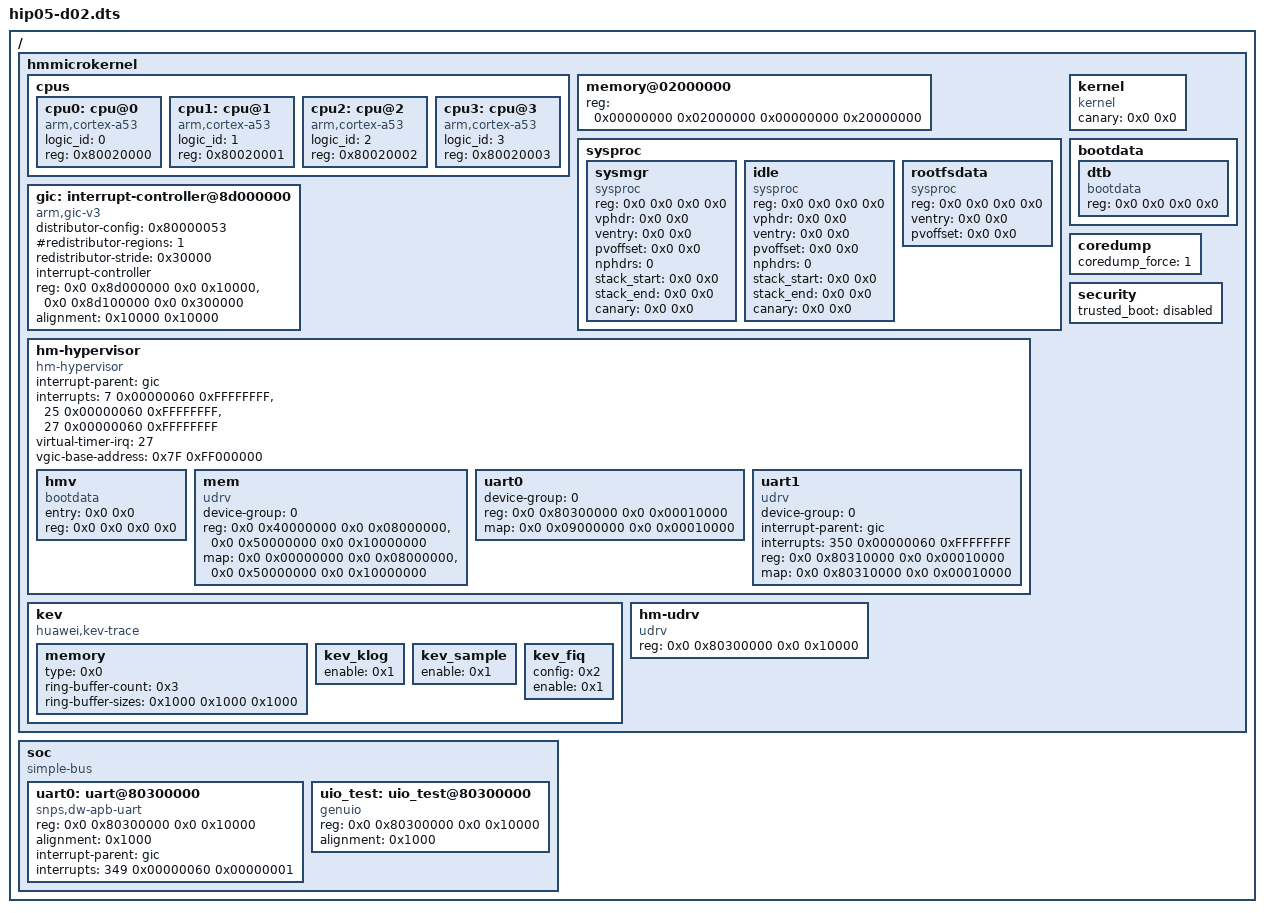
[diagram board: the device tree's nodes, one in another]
/dts-v1/;
/ { #address-cells = <2>; #size-cells = <2>; hmmicrokernel {
	#address-cells = <2>;
	#size-cells = <2>;
	cpus {
		#address-cells = <1>;
		#size-cells = <0>;
		cpu0: cpu@0 {
			compatible = "arm,cortex-a53", "arm,armv8";
			device_type = "cpu";
			logic_id = <0>;
			reg = <0x80020000>;
		};
		cpu1: cpu@1 {
			compatible = "arm,cortex-a53", "arm,armv8";
			device_type = "cpu";
			logic_id = <1>;
			reg = <0x80020001>;
		};
		cpu2: cpu@2 {
			compatible = "arm,cortex-a53", "arm,armv8";
			device_type = "cpu";
			logic_id = <2>;
			reg = <0x80020002>;
		};
		cpu3: cpu@3 {
			compatible = "arm,cortex-a53", "arm,armv8";
			device_type = "cpu";
			logic_id = <3>;
			reg = <0x80020003>;
		};
	};

	memory@02000000 {
		device_type = "memory";
		reg = <0x00000000 0x02000000 0x00000000 0x20000000>;
	};

	sysproc {
		#address-cells = <2>;
		#size-cells = <2>;
		sysmgr {
			compatible = "sysproc", "sysmgr";
			/* filled by bootloader */
			reg      = <0x0 0x0 0x0 0x0>;
			vphdr    = <0x0 0x0>;
			ventry   = <0x0 0x0>;
			pvoffset = <0x0 0x0>;
			nphdrs   = <0>;
			stack_start = <0x0 0x0>;
			stack_end = <0x0 0x0>;
			canary = <0x0 0x0>;
		};
		idle {
			compatible = "sysproc", "idle";
			/* filled by bootloader */
			reg      = <0x0 0x0 0x0 0x0>;
			vphdr    = <0x0 0x0>;
			ventry   = <0x0 0x0>;
			pvoffset = <0x0 0x0>;
			nphdrs   = <0>;
			stack_start = <0x0 0x0>;
			stack_end = <0x0 0x0>;
			canary = <0x0 0x0>;
		};
		rootfsdata {
			compatible = "sysproc", "rootfs";
			/* filled by bootloader */
			reg      = <0x0 0x0 0x0 0x0>;
			ventry   = <0x0 0x0>;
			pvoffset = <0x0 0x0>;
		};
	};

	kernel {
		compatible = "kernel";
		/* filled by bootloader */
		canary = <0x0 0x0>;
	};

	bootdata {
		#address-cells = <2>;
		#size-cells = <2>;
		dtb {
			compatible = "bootdata", "dtb";
			/* filled by bootloader */
			reg = <0x0 0x0 0x0 0x0>;
		};
	};

	gic: interrupt-controller@8d000000 {
		compatible = "arm,gic-v3";

		#address-cells = <2>;
		#size-cells = <2>;

		/* Enable group 0, Group1NS, ARE_NS, Disable Security */
		distributor-config = <0x80000053>;

		#interrupt-cells = <3>;
		#redistributor-regions = <1>;
		redistributor-stride = <0x30000>;
		interrupt-controller;
		reg =   <0x0 0x8d000000 0x0 0x10000>,	/* GICD */
			<0x0 0x8d100000 0x0 0x300000>;	/* GICR */
		alignment = <0x10000 0x10000>;
	};

	hm-hypervisor {
		compatible = "hm-hypervisor";
		#address-cells = <2>;
		#size-cells = <2>;

		interrupt-parent = <&gic>;
		interrupts = < 7 0x00000060 0xFFFFFFFF>,
			     <25 0x00000060 0xFFFFFFFF>,
			     <27 0x00000060 0xFFFFFFFF>;

		virtual-timer-irq = <27>;
		vgic-base-address = <0x7F 0xFF000000>;

		hmv {
			compatible = "bootdata";
			/* filled by bootloader */
			entry = <0x0 0x0>;
			reg = <0x0 0x0 0x0 0x0>;
		};

		mem {
			device-group = <0>;
			compatible = "udrv";
			reg = <0x0 0x40000000 0x0 0x08000000>,
			      <0x0 0x50000000 0x0 0x10000000>;
			map = <0x0 0x00000000 0x0 0x08000000>,
			      <0x0 0x50000000 0x0 0x10000000>;
		};

		uart0 {
			device-group = <0>;
			reg = <0x0 0x80300000 0x0 0x00010000>;
			map = <0x0 0x09000000 0x0 0x00010000>;
		};

		uart1 {
			device-group = <0>;
			compatible = "udrv";
			interrupt-parent = <&gic>;
			interrupts = <350 0x00000060 0xFFFFFFFF>;
			reg = <0x0 0x80310000 0x0 0x00010000>;
			map = <0x0 0x80310000 0x0 0x00010000>;
		};
	};

	kev {
		compatible = "huawei,kev-trace";

		memory {
			type = <0x0>;
			ring-buffer-count = <0x3>;
			ring-buffer-sizes = <0x1000 0x1000 0x1000>;
		};
		kev_klog {
			enable = <0x1>;
		};
		kev_sample {
			enable = <0x1>;
		};
		kev_fiq {
			config = <0x2>;
			enable = <0x1>;
		};
	};

	hm-udrv {
		compatible = "udrv";
		reg = <0x0 0x80300000 0x0 0x10000>;
	};

	coredump {
		coredump_force = <1>;
	};
	security {
		trusted_boot = "disabled";
	};
	};

	soc {
		compatible = "simple-bus";
		#address-cells = <2>;
		#size-cells = <2>;
		ranges;

		uart0: uart@80300000 {
			compatible = "snps,dw-apb-uart", "arm,pl011,uart";
			reg = <0x0 0x80300000 0x0 0x10000>;
			alignment = <0x1000>;

			interrupt-parent = <&gic>;
			interrupts = <349 0x00000060 0x00000001>;
		};

		uio_test: uio_test@80300000 {
			compatible = "genuio";
			reg = <0x0 0x80300000 0x0 0x10000>;
			alignment = <0x1000>;
		};
	};
};
